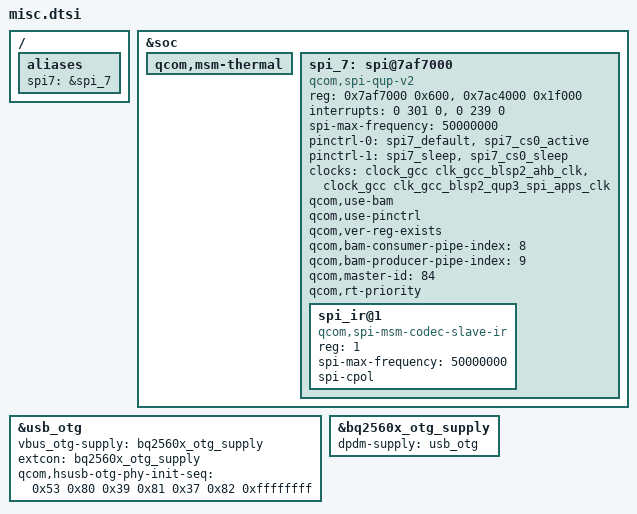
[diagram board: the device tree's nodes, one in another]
/*
 * Copyright (c) 2016, The Linux Foundation. All rights reserved.
 * Copyright (C) 2018 XiaoMi, Inc.
 *
 * This program is free software; you can redistribute it and/or modify
 * it under the terms of the GNU General Public License version 2 and
 * only version 2 as published by the Free Software Foundation.
 *
 * This program is distributed in the hope that it will be useful,
 * but WITHOUT ANY WARRANTY; without even the implied warranty of
 * MERCHANTABILITY or FITNESS FOR A PARTICULAR PURPOSE.  See the
 * GNU General Public License for more details.
 */

/ {
	aliases {
		spi7 = &spi_7;
	};
};

&soc {
	qcom,msm-thermal {
		/delete-property/ qcom,therm-reset-temp;
	};

	spi_7: spi@7af7000 { /* BLSP1 QUP3 */
		compatible = "qcom,spi-qup-v2";
		#address-cells = <1>;
		#size-cells = <0>;
		reg-names = "spi_physical", "spi_bam_physical";
		reg = <0x7af7000 0x600>,
			<0x7ac4000 0x1f000>;
		interrupt-names = "spi_irq", "spi_bam_irq";
		interrupts = <0 301 0>, <0 239 0>;
		spi-max-frequency = <50000000>;
		pinctrl-names = "spi_default", "spi_sleep";
		pinctrl-0 = <&spi7_default &spi7_cs0_active>;
		pinctrl-1 = <&spi7_sleep &spi7_cs0_sleep>;
		clocks = <&clock_gcc clk_gcc_blsp2_ahb_clk>,
			<&clock_gcc clk_gcc_blsp2_qup3_spi_apps_clk>;
		clock-names = "iface_clk", "core_clk";
		qcom,use-bam;
		qcom,use-pinctrl;
		qcom,ver-reg-exists;
		qcom,bam-consumer-pipe-index = <8>;
		qcom,bam-producer-pipe-index = <9>;
		qcom,master-id = <84>;
		qcom,rt-priority;
		status = "disabled";
	};
};

&spi_7{
        status = "ok";
        spi_ir@1 {
                compatible = "qcom,spi-msm-codec-slave-ir";
                reg = <1>;
                spi-max-frequency = <50000000>;
                spi-cpol;
                status = "ok";
        };
};

&usb_otg {
	vbus_otg-supply = <&bq2560x_otg_supply>;
	extcon = <&bq2560x_otg_supply>;
	qcom,hsusb-otg-phy-init-seq =
		<0x53 0x80 0x39 0x81 0x37 0x82 0xffffffff>;

};

&bq2560x_otg_supply {
	dpdm-supply = <&usb_otg>;
};
